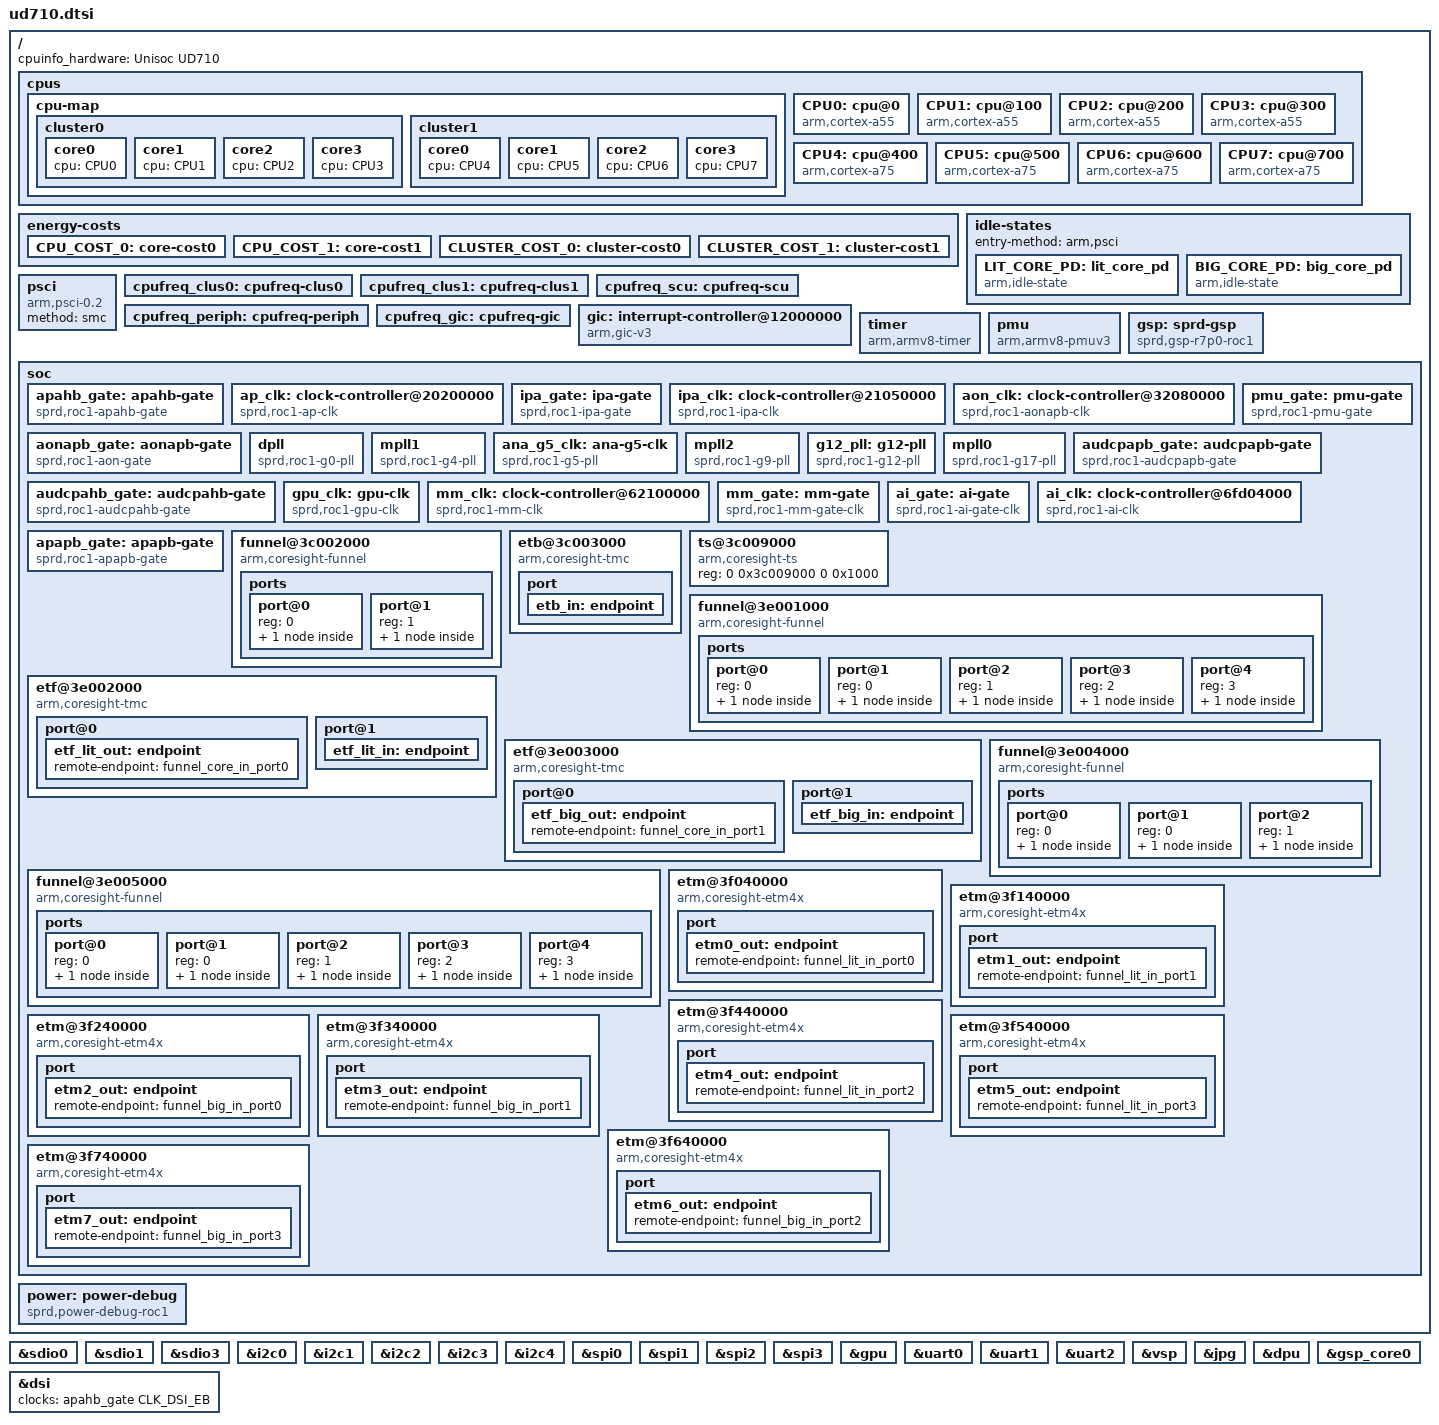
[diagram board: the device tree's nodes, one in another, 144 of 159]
/*
 * Spreadtrum Roc1 SoC DTS file
 *
 * Copyright (C) 2018, Spreadtrum Communications Inc.
 *
 * This file is licensed under a dual GPLv2 or X11 license.
 */

#include <dt-bindings/clock/sprd,roc1-clk.h>
#include "roc1.dtsi"

/ {
	cpuinfo_hardware = "Unisoc UD710";

	cpus {
		#address-cells = <2>;
		#size-cells = <0>;

		cpu-map {
			cluster0 {
				core0 {
					cpu = <&CPU0>;
				};
				core1 {
					cpu = <&CPU1>;
				};
				core2 {
					cpu = <&CPU2>;
				};
				core3 {
					cpu = <&CPU3>;
				};
			};
			cluster1 {
				core0 {
					cpu = <&CPU4>;
				};
				core1 {
					cpu = <&CPU5>;
				};
				core2 {
					cpu = <&CPU6>;
				};
				core3 {
					cpu = <&CPU7>;
				};
			};
		};

		CPU0: cpu@0 {
			device_type = "cpu";
			compatible = "arm,cortex-a55","arm,armv8";
			reg = <0x0 0x0>;
			enable-method = "psci";
			cpu-idle-states = <&LIT_CORE_PD>;
			cpufreq-data-v1 = <&cpufreq_clus0>;
			sched-energy-costs = <&CPU_COST_0 &CLUSTER_COST_0>;
			capacity-dmips-mhz = <544>;
		};
		CPU1: cpu@100 {
			device_type = "cpu";
			compatible = "arm,cortex-a55","arm,armv8";
			reg = <0x0 0x100>;
			enable-method = "psci";
			cpu-idle-states = <&LIT_CORE_PD>;
			cpufreq-data-v1 = <&cpufreq_clus0>;
			sched-energy-costs = <&CPU_COST_0 &CLUSTER_COST_0>;
			capacity-dmips-mhz = <544>;
		};
		CPU2: cpu@200 {
			device_type = "cpu";
			compatible = "arm,cortex-a55","arm,armv8";
			reg = <0x0 0x200>;
			enable-method = "psci";
			cpu-idle-states = <&LIT_CORE_PD>;
			cpufreq-data-v1 = <&cpufreq_clus0>;
			sched-energy-costs = <&CPU_COST_0 &CLUSTER_COST_0>;
			capacity-dmips-mhz = <544>;
		};
		CPU3: cpu@300 {
			device_type = "cpu";
			compatible = "arm,cortex-a55","arm,armv8";
			reg = <0x0 0x300>;
			enable-method = "psci";
			cpu-idle-states = <&LIT_CORE_PD>;
			cpufreq-data-v1 = <&cpufreq_clus0>;
			sched-energy-costs = <&CPU_COST_0 &CLUSTER_COST_0>;
			capacity-dmips-mhz = <544>;
		};
		CPU4: cpu@400 {
			device_type = "cpu";
			compatible = "arm,cortex-a75","arm,armv8";
			reg = <0x0 0x400>;
			enable-method = "psci";
			cpu-idle-states = <&BIG_CORE_PD>;
			cpufreq-data-v1 = <&cpufreq_clus1>;
			sched-energy-costs = <&CPU_COST_1 &CLUSTER_COST_1>;
			capacity-dmips-mhz = <1024>;
		};
		CPU5: cpu@500 {
			device_type = "cpu";
			compatible = "arm,cortex-a75","arm,armv8";
			reg = <0x0 0x500>;
			enable-method = "psci";
			cpu-idle-states = <&BIG_CORE_PD>;
			cpufreq-data-v1 = <&cpufreq_clus1>;
			sched-energy-costs = <&CPU_COST_1 &CLUSTER_COST_1>;
			capacity-dmips-mhz = <1024>;
		};
		CPU6: cpu@600 {
			device_type = "cpu";
			compatible = "arm,cortex-a75","arm,armv8";
			reg = <0x0 0x600>;
			enable-method = "psci";
			cpu-idle-states = <&BIG_CORE_PD>;
			cpufreq-data-v1 = <&cpufreq_clus1>;
			sched-energy-costs = <&CPU_COST_1 &CLUSTER_COST_1>;
			capacity-dmips-mhz = <1024>;
		};
		CPU7: cpu@700 {
			device_type = "cpu";
			compatible = "arm,cortex-a75","arm,armv8";
			reg = <0x0 0x700>;
			enable-method = "psci";
			cpu-idle-states = <&BIG_CORE_PD>;
			cpufreq-data-v1 = <&cpufreq_clus1>;
			sched-energy-costs = <&CPU_COST_1 &CLUSTER_COST_1>;
			capacity-dmips-mhz = <1024>;
		};
	};

	energy-costs {
		CPU_COST_0: core-cost0 {
			busy-cost-data = <
				165	59		//614MHz
				206	76		//768MHz
				329	120		//1229MHz
				397	156		//1482MHz
				418	182		//1560MHz
				460	218		//1716MHz
				488	254		//1820MHz
			>;
			idle-cost-data = <
				31		/* ACTIVE-IDLE */
				31		/* WFI */
				0		/* CORE_PD */
			>;
		};
		CPU_COST_1: core-cost1 {
			busy-cost-data = <
				621	472		//1229MHz
				748	623		//1482MHz
				776	720		//1536MHz
				880	897		//1742MHz
				945	1063		//1872MHz
				1024	1265		//2028MHz
			>;
			idle-cost-data = <
				108		/* ACTIVE-IDLE */
				108		/* WFI */
				0		/* CORE_PD */
			>;
		};
		CLUSTER_COST_0: cluster-cost0 {
			busy-cost-data = <
				164	1		//614MHz
				206	2		//768MHz
				329	3		//1229MHz
				397	4		//1482MHz
				412	5		//1560MHz
				460	6		//1716MHz
				488	7		//1820MHz
			>;
			idle-cost-data = <
				0		/* ACTIVE-IDLE */
				0		/* WFI */
				0		/* CORE_PD */
			>;
		};
		CLUSTER_COST_1: cluster-cost1 {
			busy-cost-data = <
				621	36		//1229MHz
				748	40		//1482MHz
				776	43		//1536MHz
				880	47		//1742MHz
				945	52		//1872MHz
				1024	58		//2028MHz
			>;
			idle-cost-data = <
				45		/* ACTIVE-IDLE */
				45		/* WFI */
				45		/* CORE_PD */
			>;
		};
	};

	idle-states {
		entry-method = "arm,psci";
		LIT_CORE_PD: lit_core_pd {
			compatible = "arm,idle-state";
			entry-latency-us = <0xffffffff>;
			exit-latency-us = <0xffffffff>;
			min-residency-us = <0xffffffff>;
			local-timer-stop;
			arm,psci-suspend-param = <0x00010000>;
		};
		BIG_CORE_PD: big_core_pd {
			compatible = "arm,idle-state";
			entry-latency-us = <4000>;
			exit-latency-us = <4000>;
			min-residency-us = <10000>;
			local-timer-stop;
			arm,psci-suspend-param = <0x00010000>;
		};
	};

	psci {
		compatible = "arm,psci-0.2";
		method = "smc";
	};

	cpufreq_clus0: cpufreq-clus0 {
		cpufreq-cluster-id = <0>;
		cpufreq-sub-clusters =  <&cpufreq_scu>,
					<&cpufreq_periph>,
					<&cpufreq_gic>;
		clock-latency = <50000>;
		voltage-latency = <6413>;

		operating-points = <
			/*kHZ	uV*/
			1820000 1000000
			1716000 1000000
			1560000 1000000
			1482000 1000000
			1228800 800000
			1144000 800000
			962000  800000
			768000  800000
			614400  750000
		>;
	};

	cpufreq_clus1: cpufreq-clus1 {
		cpufreq-cluster-id = <1>;
		cpufreq-sub-clusters =  <&cpufreq_scu>,
					<&cpufreq_periph>,
					<&cpufreq_gic>;
		clock-latency = <50000>;
		voltage-latency = <0>;
		operating-points = <
			/*kHZ	uV*/
			2028000 1000000
			1872000 1000000
			1742000 1000000
			1536000 1000000
			1482000 800000
			1228800 750000
		>;
	};

	cpufreq_scu: cpufreq-scu {
		cpufreq-cluster-id = <2>;
		clock-latency = <50000>;
		voltage-latency = <0>;
		operating-points = <
			/*kHZ	uV*/
			1300000 1000000
			1248000 1000000
			1170000 1000000
			962000  800000
			858000  800000
			768000  800000
			650000  800000
			520000  700000
		>;
	};

	cpufreq_periph: cpufreq-periph {
		cpufreq-cluster-id = <3>;
		clock-latency = <50000>;
		voltage-latency = <0>;
		operating-points = <
			/*kHZ	uV*/
			512000 800000
			384000 800000
			256000 800000
			153600 700000
		>;
	};

	cpufreq_gic: cpufreq-gic {
		cpufreq-cluster-id = <4>;
		clock-latency = <50000>;
		voltage-latency = <0>;
		operating-points = <
			/*kHZ	uV*/
			512000 1000000
			384000 800000
			256000 800000
			192000 800000
			153600 700000
		>;
	};

	gic: interrupt-controller@12000000 {
		compatible = "arm,gic-v3";
		#interrupt-cells = <3>;
		#address-cells = <2>;
		#size-cells = <2>;
		ranges;
		redistributor-stride = <0x0 0x20000>;	// 128KB stride
		#redistributor-regions = <1>;
		interrupt-controller;
		reg = <0x0 0x12000000 0 0x20000>,	// GICD
			<0x0 0x12040000 0 0x100000>;	// GICR
		interrupts = <1 9 4>;
	};

	timer {
		compatible = "arm,armv8-timer";
		interrupts = <GIC_PPI 13 IRQ_TYPE_LEVEL_HIGH>, /* Physical Secure PPI */
			<GIC_PPI 14 IRQ_TYPE_LEVEL_HIGH>, /* Physical Non-Secure PPI */
			<GIC_PPI 11 IRQ_TYPE_LEVEL_HIGH>, /* Virtual PPI */
			<GIC_PPI 10 IRQ_TYPE_LEVEL_HIGH>; /* Hipervisor PPI */
		arm,no-tick-in-suspend;
	};

	pmu {
		compatible = "arm,armv8-pmuv3";
		interrupts = <GIC_SPI 112 IRQ_TYPE_LEVEL_HIGH>,
				<GIC_SPI 113 IRQ_TYPE_LEVEL_HIGH>,
				<GIC_SPI 114 IRQ_TYPE_LEVEL_HIGH>,
				<GIC_SPI 115 IRQ_TYPE_LEVEL_HIGH>,
				<GIC_SPI 116 IRQ_TYPE_LEVEL_HIGH>,
				<GIC_SPI 117 IRQ_TYPE_LEVEL_HIGH>,
				<GIC_SPI 118 IRQ_TYPE_LEVEL_HIGH>,
				<GIC_SPI 119 IRQ_TYPE_LEVEL_HIGH>;
	};

	gsp: sprd-gsp {
		compatible = "sprd,gsp-r7p0-roc1";
		name = "sprd-gsp";
		core-cnt = <1>;
		io-cnt = <7>;
		cores = <&gsp_core0>;
	};

	soc {
		apahb_gate: apahb-gate {
			compatible = "sprd,roc1-apahb-gate";
			sprd,syscon = <&ap_ahb_regs>; /* 0x20100000 */
			clocks = <&ext_26m>;
			#clock-cells = <1>;
		};

		ap_clk: clock-controller@20200000 {
			compatible = "sprd,roc1-ap-clk";
			reg = <0 0x20200000 0 0x1000>;
			clocks = <&ext_26m>;
			#clock-cells = <1>;
		};

		ipa_gate: ipa-gate {
			compatible = "sprd,roc1-ipa-gate";
			sprd,syscon = <&ipa_ahb_regs>;
			clocks = <&ext_26m>;
			#clock-cells = <1>;
		};

		ipa_clk: clock-controller@21050000 {
			compatible = "sprd,roc1-ipa-clk";
			reg = <0 0x21050000 0 0x1000>;
			clocks = <&ext_26m>;
			#clock-cells = <1>;
		};

		aon_clk: clock-controller@32080000 {
			compatible = "sprd,roc1-aonapb-clk";
			reg = <0 0x32080000 0 0x1000>;
			clocks = <&ext_26m>;
			#clock-cells = <1>;
		};

		aonapb_gate: aonapb-gate {
			compatible = "sprd,roc1-aon-gate";
			sprd,syscon = <&aon_apb_regs>; /* 0x32090000 */
			clocks = <&ext_26m>;
			#clock-cells = <1>;
		};

		pmu_gate: pmu-gate {
			compatible = "sprd,roc1-pmu-gate";
			sprd,syscon = <&pmu_apb_regs>; /* 0x32280000 */
			clocks = <&ext_26m>;
			#clock-cells = <1>;
		};

		dpll: dpll {
			compatible = "sprd,roc1-g0-pll";
			reg = <0 0x32390000 0 0x3000>; /* 0x32390000 */
			clocks = <&aon_clk CLK_ANALOG_IO_APB>;
			#clock-cells = <1>;
		};

		mpll1: mpll1 {
			compatible = "sprd,roc1-g4-pll";
			sprd,syscon = <&anlg_phy_g4_regs>; /* 0x323c0000 */
			clocks = <&aon_clk CLK_ANALOG_IO_APB>;
			#clock-cells = <1>;
		};

		ana_g5_clk: ana-g5-clk {
			compatible = "sprd,roc1-g5-pll";
			sprd,syscon = <&anlg_phy_g5_regs>; /* 0x323d0000 */
			clocks = <&aon_clk CLK_ANALOG_IO_APB>;
			#clock-cells = <1>;
		};

		mpll2: mpll2 {
			compatible = "sprd,roc1-g9-pll";
			reg = <0 0x32410000 0 0x3000>; /* 0x32410000 */
			clocks = <&aon_clk CLK_ANALOG_IO_APB>;
			#clock-cells = <1>;
		};

		g12_pll: g12-pll {
			compatible = "sprd,roc1-g12-pll";
			reg = <0 0x32414000 0 0x3000>; /* 0x32414000 */
			clocks = <&aon_clk CLK_ANALOG_IO_APB>;
			#clock-cells = <1>;
		};

		mpll0: mpll0 {
			compatible = "sprd,roc1-g17-pll";
			reg = <0 0x32418000 0 0x3000>; /* 0x32418000 */
			clocks = <&aon_clk CLK_ANALOG_IO_APB>;
			#clock-cells = <1>;
		};

		audcpapb_gate: audcpapb-gate {
			compatible = "sprd,roc1-audcpapb-gate";
			sprd,syscon = <&audcp_apb_regs>; /* 0x3350d000 */
			clocks = <&ext_26m>;
			#clock-cells = <1>;
		};

		audcpahb_gate: audcpahb-gate {
			compatible = "sprd,roc1-audcpahb-gate";
			sprd,syscon = <&audcp_ahb_regs>; /* 0x335e0000 */
			clocks = <&ext_26m>;
			#clock-cells = <1>;
		};

		gpu_clk: gpu-clk {
			compatible = "sprd,roc1-gpu-clk";
			sprd,syscon = <&gpu_apb_regs>;	/* 0x60100000 */
			clocks = <&aon_clk CLK_AP_GPU>;
			syscons = <&aon_apb_regs REG_AON_APB_APB_EB0 MASK_AON_APB_GPU_EB>,
				  <&pmu_apb_regs REG_PMU_APB_PD_GPU_TOP_CFG0 MASK_PMU_APB_PD_GPU_TOP_FORCE_SHUTDOWN>;
			syscon-names = "enable", "power";
			#clock-cells = <1>;
		};

		mm_clk: clock-controller@62100000 {
			compatible = "sprd,roc1-mm-clk";
			reg = <0 0x62100000 0 0x1000>;
			clocks = <&aonapb_gate CLK_MM_EB>;
			#clock-cells = <1>;
		};

		mm_gate: mm-gate {
			compatible = "sprd,roc1-mm-gate-clk";
			sprd,syscon = <&mm_ahb_regs>;
			clocks = <&aonapb_gate CLK_MM_EB>;
			syscons = <&aon_apb_regs REG_AON_APB_APB_EB0 MASK_AON_APB_MM_EB>,
				  <&pmu_apb_regs REG_PMU_APB_PD_MM_TOP_CFG MASK_PMU_APB_PD_MM_TOP_FORCE_SHUTDOWN>;
			syscon-names = "enable", "power";
			#clock-cells = <1>;
		};

		ai_gate: ai-gate {
			compatible = "sprd,roc1-ai-gate-clk";
			sprd,syscon = <&ai_apb_regs>;
			clocks = <&aonapb_gate CLK_AI_EB>;
			#clock-cells = <1>;
		};

		ai_clk: clock-controller@6fd04000 {
			compatible = "sprd,roc1-ai-clk";
			reg = <0 0x6fd04000 0 0x1000>;
			clocks = <&ext_26m>;
			syscons = <&aon_apb_regs REG_AON_APB_APB_EB0 MASK_AON_APB_AI_EB>,
				  <&pmu_apb_regs REG_PMU_APB_PD_AI_SYS_CFG MASK_PMU_APB_PD_AI_SYS_FORCE_SHUTDOWN>;
			syscon-names = "enable", "power";
			#clock-cells = <1>;
		};

		apapb_gate: apapb-gate {
			compatible = "sprd,roc1-apapb-gate";
			sprd,syscon = <&ap_apb_regs>; /* 0x71000000 */
			clocks = <&ext_26m>;
			#clock-cells = <1>;
		};

		funnel@3c002000 {
			compatible = "arm,coresight-funnel", "arm,primecell";
			reg = <0 0x3c002000 0 0x1000>;
			clocks = <&ext_26m>;
			clock-names = "apb_pclk";
			ports {
				#address-cells = <1>;
				#size-cells = <0>;

				port@0 {
					reg = <0>;
					funnel_soc_out_port: endpoint {
						remote-endpoint = <&etb_in>;
					};
				};

				port@1 {
					reg = <1>;
					funnel_soc_in_port: endpoint {
						slave-mode;
						remote-endpoint = <&funnel_core_out_port>;
					};
				};
			};
		};

		etb@3c003000 {
			compatible = "arm,coresight-tmc", "arm,primecell";
			reg = <0 0x3c003000 0 0x1000>;
			clocks = <&ext_26m>;
			clock-names = "apb_pclk";
			port {
				etb_in: endpoint {
					slave-mode;
					remote-endpoint = <&funnel_soc_out_port>;
				};
			};
		};

		ts@3c009000 {
			compatible = "arm,coresight-ts", "arm,primecell";
			reg = <0 0x3c009000 0 0x1000>;
		};

		funnel@3e001000 {
			compatible = "arm,coresight-funnel", "arm,primecell";
			reg = <0 0x3e001000 0 0x1000>;
			clocks = <&ext_26m>;
			clock-names = "apb_pclk";

			ports {
				#address-cells = <1>;
				#size-cells = <0>;

				port@0 {
					reg = <0>;
					funnel_lit_out_port: endpoint {
						remote-endpoint = <&etf_lit_in>;
					};
				};

				port@1 {
					reg = <0>;
					funnel_lit_in_port0: endpoint {
						slave-mode;
						remote-endpoint = <&etm0_out>;
					};
				};

				port@2 {
					reg = <1>;
					funnel_lit_in_port1: endpoint {
						slave-mode;
						remote-endpoint = <&etm1_out>;
					};
				};

				port@3 {
					reg = <2>;
					funnel_lit_in_port2: endpoint {
						slave-mode;
						remote-endpoint = <&etm4_out>;
					};
				};

				port@4 {
					reg = <3>;
					funnel_lit_in_port3: endpoint {
						slave-mode;
						remote-endpoint = <&etm5_out>;
					};
				};
			};
		};

		etf@3e002000 {
			compatible = "arm,coresight-tmc", "arm,primecell";
			reg = <0 0x3e002000 0 0x1000>;
			clocks = <&ext_26m>;
			clock-names = "apb_pclk";

			port@0 {
				etf_lit_out: endpoint {
					remote-endpoint = <&funnel_core_in_port0>;
				};
			};

			port@1 {
				etf_lit_in: endpoint {
					slave-mode;
					remote-endpoint = <&funnel_lit_out_port>;
				};
			};
		};

		etf@3e003000 {
			compatible = "arm,coresight-tmc", "arm,primecell";
			reg = <0 0x3e003000 0 0x1000>;
			clocks = <&ext_26m>;
			clock-names = "apb_pclk";

			port@0 {
				etf_big_out: endpoint {
					remote-endpoint = <&funnel_core_in_port1>;
				};
			};

			port@1 {
				etf_big_in: endpoint {
					slave-mode;
					remote-endpoint = <&funnel_big_out_port>;
				};
			};
		};

		funnel@3e004000 {
			compatible = "arm,coresight-funnel", "arm,primecell";
			reg = <0 0x3e004000 0 0x1000>;
			clocks = <&ext_26m>;
			clock-names = "apb_pclk";
			ports {
				#address-cells = <1>;
				#size-cells = <0>;

				port@0 {
					reg = <0>;
					funnel_core_out_port: endpoint {
						remote-endpoint = <&funnel_soc_in_port>;
					};
				};

				port@1 {
					reg = <0>;
					funnel_core_in_port0: endpoint {
						slave-mode;
						remote-endpoint = <&etf_lit_out>;
					};
				};

				port@2 {
					reg = <1>;
					funnel_core_in_port1: endpoint {
						slave-mode;
						remote-endpoint = <&etf_big_out>;
					};
				};
			};
		};

		funnel@3e005000 {
			compatible = "arm,coresight-funnel", "arm,primecell";
			reg = <0 0x3e005000 0 0x1000>;
			clocks = <&ext_26m>;
			clock-names = "apb_pclk";

			ports {
				#address-cells = <1>;
				#size-cells = <0>;

				port@0 {
					reg = <0>;
					funnel_big_out_port: endpoint {
						remote-endpoint = <&etf_big_in>;
					};
				};

				port@1 {
					reg = <0>;
					funnel_big_in_port0: endpoint {
						slave-mode;
						remote-endpoint = <&etm2_out>;
					};
				};

				port@2 {
					reg = <1>;
					funnel_big_in_port1: endpoint {
						slave-mode;
						remote-endpoint = <&etm3_out>;
					};
				};

				port@3 {
					reg = <2>;
					funnel_big_in_port2: endpoint {
						slave-mode;
						remote-endpoint = <&etm6_out>;
					};
				};

				port@4 {
					reg = <3>;
					funnel_big_in_port3: endpoint {
						slave-mode;
						remote-endpoint = <&etm7_out>;
					};
				};
			};
		};

		etm@3f040000 {
			compatible = "arm,coresight-etm4x", "arm,primecell";
			reg = <0 0x3f040000 0 0x1000>;
			cpu = <&CPU0>;
			clocks = <&ext_26m>, <&aon_clk CLK_CSSYS>, <&g12_pll CLK_TWPLL_512M>;
			clock-names = "apb_pclk", "clk_cs", "cs_src";

			port {
				etm0_out: endpoint {
					remote-endpoint = <&funnel_lit_in_port0>;
				};
			};
		};

		etm@3f140000 {
			compatible = "arm,coresight-etm4x", "arm,primecell";
			reg = <0 0x3f140000 0 0x1000>;
			cpu = <&CPU1>;
			clocks = <&ext_26m>, <&aon_clk CLK_CSSYS>, <&g12_pll CLK_TWPLL_512M>;
			clock-names = "apb_pclk", "clk_cs", "cs_src";

			port {
				etm1_out: endpoint {
					remote-endpoint = <&funnel_lit_in_port1>;
				};
			};
		};

		etm@3f240000 {
			compatible = "arm,coresight-etm4x", "arm,primecell";
			reg = <0 0x3f240000 0 0x1000>;
			cpu = <&CPU2>;
			clocks = <&ext_26m>, <&aon_clk CLK_CSSYS>, <&g12_pll CLK_TWPLL_512M>;
			clock-names = "apb_pclk", "clk_cs", "cs_src";

			port {
				etm2_out: endpoint {
					remote-endpoint = <&funnel_big_in_port0>;
				};
			};
		};

		etm@3f340000 {
			compatible = "arm,coresight-etm4x", "arm,primecell";
			reg = <0 0x3f340000 0 0x1000>;
			cpu = <&CPU3>;
			clocks = <&ext_26m>, <&aon_clk CLK_CSSYS>, <&g12_pll CLK_TWPLL_512M>;
			clock-names = "apb_pclk", "clk_cs", "cs_src";

			port {
				etm3_out: endpoint {
					remote-endpoint = <&funnel_big_in_port1>;
				};
			};
		};

		etm@3f440000 {
			compatible = "arm,coresight-etm4x", "arm,primecell";
			reg = <0 0x3f440000 0 0x1000>;
			cpu = <&CPU4>;
			clocks = <&ext_26m>, <&aon_clk CLK_CSSYS>, <&g12_pll CLK_TWPLL_512M>;
			clock-names = "apb_pclk", "clk_cs", "cs_src";

			port {
				etm4_out: endpoint {
					remote-endpoint = <&funnel_lit_in_port2>;
				};
			};
		};

		etm@3f540000 {
			compatible = "arm,coresight-etm4x", "arm,primecell";
			reg = <0 0x3f540000 0 0x1000>;
			cpu = <&CPU5>;
			clocks = <&ext_26m>, <&aon_clk CLK_CSSYS>, <&g12_pll CLK_TWPLL_512M>;
			clock-names = "apb_pclk", "clk_cs", "cs_src";

			port {
				etm5_out: endpoint {
					remote-endpoint = <&funnel_lit_in_port3>;
				};
			};
		};

		etm@3f640000 {
			compatible = "arm,coresight-etm4x", "arm,primecell";
			reg = <0 0x3f640000 0 0x1000>;
			cpu = <&CPU6>;
			clocks = <&ext_26m>, <&aon_clk CLK_CSSYS>, <&g12_pll CLK_TWPLL_512M>;
			clock-names = "apb_pclk", "clk_cs", "cs_src";

			port {
				etm6_out: endpoint {
					remote-endpoint = <&funnel_big_in_port2>;
				};
			};
		};

		etm@3f740000 {
			compatible = "arm,coresight-etm4x", "arm,primecell";
			reg = <0 0x3f740000 0 0x1000>;
			cpu = <&CPU7>;
			clocks = <&ext_26m>, <&aon_clk CLK_CSSYS>, <&g12_pll CLK_TWPLL_512M>;
			clock-names = "apb_pclk", "clk_cs", "cs_src";

			port {
				etm7_out: endpoint {
					remote-endpoint = <&funnel_big_in_port3>;
				};
			};
		};
	};

	power: power-debug {
		compatible = "sprd,power-debug-roc1";
		#address-cells = <1>;
		#size-cells = <0>;

		sprd,enable = <1>;
		sprd,scan-interval = <30>;

		sprd,sys-ap-ahb = <&ap_ahb_regs>;
		sprd,sys-ap-apb = <&ap_apb_regs>;
		sprd,sys-pmu-apb = <&pmu_apb_regs>;
		sprd,sys-aon-apb = <&aon_apb_regs>;
		sprd,sys-ap-intc = <&ap_intc0_regs &ap_intc1_regs
				&ap_intc2_regs &ap_intc3_regs
				&ap_intc4_regs &ap_intc5_regs>;
	};
};

&sdio0 {
	clock-names = "sdio_clk", "sdio_clk_source","sdio_ahb_enable";
	clocks = <&ap_clk CLK_AP_SDIO0_2X>,
		 <&ana_g5_clk CLK_RPLL>,
		 <&apapb_gate CLK_SDIO0_EB>;
};

&sdio1 {
	clock-names = "sdio_clk","sdio_clk_source","sdio_ahb_enable";
	clocks = <&ap_clk CLK_AP_SDIO1_2X>,
		 <&g12_pll CLK_LPLL_409M6>,
		 <&apapb_gate CLK_SDIO1_EB>;
};

&sdio3 {
	clock-names = "sdio_clk","sdio_clk_source","sdio_ahb_enable";
	clocks = <&ap_clk CLK_AP_EMMC_2X>,
		 <&ana_g5_clk CLK_RPLL>,
		 <&apapb_gate CLK_EMMC_EB>;
};

&i2c0 {
	clock-names ="enable", "i2c", "source";
	clocks = <&apapb_gate CLK_I2C0_EB>,
		 <&ap_clk CLK_AP_I2C0>, <&ext_26m>;
};

&i2c1 {
	clock-names ="enable", "i2c", "source";
	clocks = <&apapb_gate CLK_I2C1_EB>,
		 <&ap_clk CLK_AP_I2C1>, <&ext_26m>;
};

&i2c2 {
	clock-names ="enable", "i2c", "source";
	clocks = <&apapb_gate CLK_I2C2_EB>,
		 <&ap_clk CLK_AP_I2C2>, <&ext_26m>;
};

&i2c3 {
	clock-names ="enable", "i2c", "source";
	clocks = <&apapb_gate CLK_I2C3_EB>,
		 <&ap_clk CLK_AP_I2C3>, <&ext_26m>;
};

&i2c4 {
	clock-names ="enable", "i2c", "source";
	clocks = <&apapb_gate CLK_I2C4_EB>,
		 <&ap_clk CLK_AP_I2C4>, <&ext_26m>;
};

&spi0 {
	clock-names = "enable", "spi", "source";
	clocks = <&apapb_gate CLK_SPI0_EB>,
	<&ap_clk CLK_AP_SPI0>, <&g12_pll CLK_TWPLL_192M>;
};

&spi1 {
	clock-names = "enable", "spi", "source";
	clocks = <&apapb_gate CLK_SPI1_EB>,
	<&ap_clk CLK_AP_SPI1>, <&g12_pll CLK_TWPLL_192M>;
};

&spi2 {
	clock-names = "enable", "spi", "source";
	clocks = <&apapb_gate CLK_SPI2_EB>,
	<&ap_clk CLK_AP_SPI2>, <&g12_pll CLK_TWPLL_192M>;
};

&spi3 {
	clock-names = "enable", "spi", "source";
	clocks = <&apapb_gate CLK_SPI3_EB>,
	<&ap_clk CLK_AP_SPI3>, <&g12_pll CLK_TWPLL_192M>;
};

&gpu {
	clocks = <&aonapb_gate CLK_GPU_EB>,
		<&gpu_clk CLK_GPU_CORE_EB>, <&gpu_clk CLK_GPU_CORE>,
		<&gpu_clk CLK_GPU_MEM_EB>, <&gpu_clk CLK_GPU_MEM>,
		<&gpu_clk CLK_GPU_SYS_EB>,
		<&g12_pll CLK_TWPLL_384M>, <&g12_pll CLK_TWPLL_512M>,
		<&g12_pll CLK_LPLL_614M4>, <&g12_pll CLK_TWPLL_768M>,
		<&g12_pll CLK_GPLL>;
};

&sdio0 {
	syscons = <&aon_apb_regs REG_AON_APB_SDIO0_CTRL_REG MASK_AON_APB_SDIO0_EMMC_CARD_PRESENT_32K>,
		  <&aon_apb_regs REG_AON_APB_SDIO0_CTRL_REG MASK_AON_APB_SDIO0_EMMC_CARD_PROTECT_32K>,
		  <&aon_apb_regs REG_AON_APB_SDIO0_CTRL_REG MASK_AON_APB_SDIO0_EMMC_CARDDET_DBNC_EN_32K>,
		  <&aon_apb_regs REG_AON_APB_SDIO0_CTRL_REG MASK_AON_APB_SDIO0_EMMC_CARDDET_DBNC_THD_32K>;
	syscon-names =  "sd_detect_pol",
			"sd_hotplug_protect_en",
			"sd_hotplug_debounce_en",
			"sd_hotplug_debounce_cn";
};

&uart0 {
	clock-names = "enable", "uart", "source";
	clocks = <&apapb_gate CLK_UART0_EB>,
		 <&ap_clk CLK_AP_UART0>,
		 <&ext_26m>;
};

&uart1 {
	clock-names = "enable", "uart", "source";
	clocks = <&apapb_gate CLK_UART1_EB>,
		 <&ap_clk CLK_AP_UART1>,
		 <&ext_26m>;
};

&uart2 {
	clock-names = "enable", "uart", "source";
	clocks = <&apapb_gate CLK_UART2_EB>,
		 <&ap_clk CLK_AP_UART2>,
		 <&ext_26m>;
};

&vsp {
	clock-names = "clk_ahb_gate_vsp_eb",
			"clk_src_256m",
			"clk_src_307m2",
			"clk_src_384m",
			"clk_src_512m",
			"clk_vsp";
	clocks = <&apahb_gate CLK_VSP_EB>,
			<&g12_pll CLK_TWPLL_256M>,
			<&g12_pll CLK_TWPLL_307M2>,
			<&g12_pll CLK_TWPLL_384M>,
			<&g12_pll CLK_TWPLL_512M>,
			<&ap_clk CLK_AP_VSP>;
};

&jpg {
	clock-names = "jpg_domain_eb",
			"jpg_dev_eb",
			"jpg_ckg_eb",
			"jpg_clk",
			"clk_src_76m8",
			"clk_src_128m",
			"clk_src_256m",
			"clk_src_384m";
	clocks = <&aonapb_gate CLK_MM_EB>,
			<&mm_gate CLK_MM_JPG_EB>,
			<&mm_gate CLK_MM_CKG_EB>,
			<&mm_clk CLK_JPG>,
			<&g12_pll CLK_TWPLL_76M8>,
			<&g12_pll CLK_TWPLL_128M>,
			<&g12_pll CLK_TWPLL_256M>,
			<&g12_pll CLK_TWPLL_384M>;
};

&dpu {
	clock-names = "clk_src_128m",
			"clk_src_153m6",
			"clk_src_192m",
			"clk_src_256m",
			"clk_src_307m2",
			"clk_src_384m",
			"clk_dpu_core",
			"clk_dpu_dpi",
			"clk_ap_ahb_disp_eb";

	clocks = <&g12_pll CLK_TWPLL_128M>,
		<&g12_pll CLK_TWPLL_153M6>,
		<&g12_pll CLK_TWPLL_192M>,
		<&g12_pll CLK_TWPLL_256M>,
		<&g12_pll CLK_TWPLL_307M2>,
		<&g12_pll CLK_TWPLL_384M>,
		<&ap_clk CLK_AP_DISPC0>,
		<&ap_clk CLK_AP_DISPC0_DPI>,
		<&apahb_gate CLK_DISPC_EB>;
};

&dsi {
	clock-names = "clk_ap_ahb_dsi_eb";
	clocks = <&apahb_gate CLK_DSI_EB>;
};

&gsp_core0 {
	clock-names =	"clk_dpu_core_src",
			"clk_dpu_core",
			"clk_ap_ahb_disp_eb";

	clocks =	<&g12_pll CLK_TWPLL_384M>,
			<&ap_clk CLK_AP_DISPC0>,
			<&apahb_gate CLK_DISPC_EB>;
};
